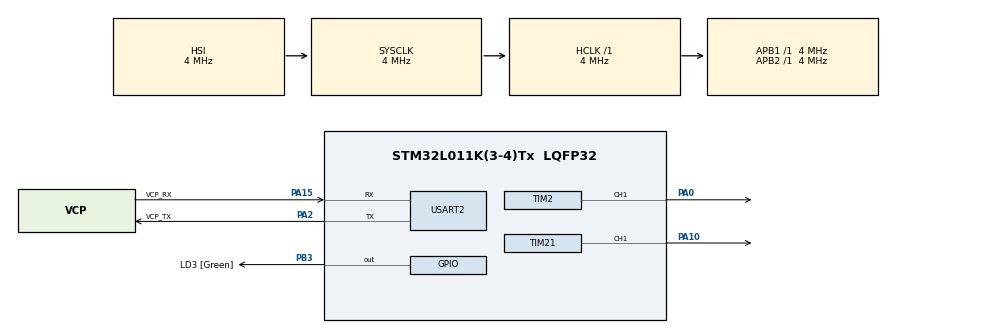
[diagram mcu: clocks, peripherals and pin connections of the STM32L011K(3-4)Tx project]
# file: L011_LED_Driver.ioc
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Mcu.Family=STM32L0
Mcu.Name=STM32L011K(3-4)Tx
Mcu.Package=LQFP32
PA0-CK_IN.Signal=S_TIM2_CH1
PA10.Signal=S_TIM21_CH1
PA13.GPIO_Label=TMS
PA13.Mode=Serial_Wire
PA13.Signal=SYS_SWDIO
PA14.GPIO_Label=TCK
PA14.Mode=Serial_Wire
PA14.Signal=SYS_SWCLK
PA15.GPIO_Label=VCP_RX
PA15.Mode=Asynchronous
PA15.Signal=USART2_RX
PA2.GPIO_Label=VCP_TX
PA2.Mode=Asynchronous
PA2.Signal=USART2_TX
PB3.GPIO_Label=LD3 [Green]
PB3.Signal=GPIO_Output
PC14-OSC32_IN.Mode=LSE-External-Oscillator
PC14-OSC32_IN.Signal=RCC_OSC32_IN
PC15-OSC32_OUT.Mode=LSE-External-Oscillator
PC15-OSC32_OUT.Signal=RCC_OSC32_OUT
ProjectManager.HeapSize=0x200
ProjectManager.StackSize=0x400
ProjectManager.TargetToolchain=STM32CubeIDE
RCC.ADCFreq_Value=4000000
RCC.AHBFreq_Value=4000000
RCC.APB1Freq_Value=4000000
RCC.APB1TimFreq_Value=4000000
RCC.APB2Freq_Value=4000000
RCC.APB2TimFreq_Value=4000000
RCC.HCLKFreq_Value=4000000
RCC.HSE_VALUE=8000000
RCC.HSI16_VALUE=16000000
RCC.HSI48_VALUE=48000000
RCC.HSIRCDiv=4
RCC.HSI_VALUE=4000000
RCC.MSIClockRange=RCC_MSIRANGE_6
RCC.MSI_VALUE=4194000
RCC.PLLMUL=RCC_PLLMUL_4
RCC.SYSCLKFreq_VALUE=4000000
RCC.SYSCLKSource=RCC_SYSCLKSOURCE_HSI
RCC.VCOOutputFreq_Value=16000000
SH.S_TIM21_CH1.0=TIM21_CH1,PWM Generation1 CH1
SH.S_TIM2_CH1.0=TIM2_CH1,PWM Generation1 CH1
TIM2.Channel-PWM\ Generation1\ CH1=TIM_CHANNEL_1
TIM2.Period=999
TIM2.Prescaler=3
TIM21.Channel-PWM\ Generation1\ CH1=TIM_CHANNEL_1
TIM21.Period=999
TIM21.Prescaler=3
USART2.VirtualMode-Asynchronous=VM_ASYNC
board=NUCLEO-L011K4

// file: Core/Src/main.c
/* USER CODE BEGIN Header */
/**
  ******************************************************************************
  * @file           : main.c
  * @brief          : Main program body
  ******************************************************************************
  * @attention
  *
  * Copyright (c) 2022 STMicroelectronics.
  * All rights reserved.
  *
  * This software is licensed under terms that can be found in the LICENSE file
  * in the root directory of this software component.
  * If no LICENSE file comes with this software, it is provided AS-IS.
  *
  ******************************************************************************
  */
/* USER CODE END Header */
#include "main.h"

TIM_HandleTypeDef htim2;
TIM_HandleTypeDef htim21;

UART_HandleTypeDef huart2;

void SystemClock_Config(void);
static void MX_GPIO_Init(void);
static void MX_USART2_UART_Init(void);
static void MX_TIM21_Init(void);
static void MX_TIM2_Init(void);

int main(void)
{

  /* MCU Configuration--------------------------------------------------------*/

  /* Reset of all peripherals, Initializes the Flash interface and the Systick. */
  HAL_Init();

  /* Configure the system clock */
  SystemClock_Config();

  /* Initialize all configured peripherals */
  MX_GPIO_Init();
  MX_USART2_UART_Init();
  MX_TIM21_Init();
  MX_TIM2_Init();
  /* USER CODE BEGIN 2 */

  /* Both PWM at 51% (dead time included) */
  __HAL_TIM_SET_COMPARE(&htim21, TIM_CHANNEL_1, 509);
  __HAL_TIM_SET_COMPARE(&htim2, TIM_CHANNEL_1, 509);

  /* Second PWM phase */
  __HAL_TIM_SET_COUNTER(&htim21, 499);

  /* Start both PWM */
  HAL_TIM_PWM_Start(&htim2, TIM_CHANNEL_1);
  HAL_TIM_PWM_Start(&htim21, TIM_CHANNEL_1);

  /* USER CODE END 2 */

  /* Infinite loop */
  while (1)
  {

  }
}

void SystemClock_Config(void)
{
  RCC_OscInitTypeDef RCC_OscInitStruct = {0};
  RCC_ClkInitTypeDef RCC_ClkInitStruct = {0};
  RCC_PeriphCLKInitTypeDef PeriphClkInit = {0};

  /** Configure the main internal regulator output voltage
  */
  __HAL_PWR_VOLTAGESCALING_CONFIG(PWR_REGULATOR_VOLTAGE_SCALE1);
  /** Initializes the RCC Oscillators according to the specified parameters
  * in the RCC_OscInitTypeDef structure.
  */
  RCC_OscInitStruct.OscillatorType = RCC_OSCILLATORTYPE_HSI;
  RCC_OscInitStruct.HSIState = RCC_HSI_DIV4;
  RCC_OscInitStruct.HSICalibrationValue = RCC_HSICALIBRATION_DEFAULT;
  RCC_OscInitStruct.PLL.PLLState = RCC_PLL_NONE;
  if (HAL_RCC_OscConfig(&RCC_OscInitStruct) != HAL_OK)
  {
    Error_Handler();
  }
  /** Initializes the CPU, AHB and APB buses clocks
  */
  RCC_ClkInitStruct.ClockType = RCC_CLOCKTYPE_HCLK|RCC_CLOCKTYPE_SYSCLK
                              |RCC_CLOCKTYPE_PCLK1|RCC_CLOCKTYPE_PCLK2;
  RCC_ClkInitStruct.SYSCLKSource = RCC_SYSCLKSOURCE_HSI;
  RCC_ClkInitStruct.AHBCLKDivider = RCC_SYSCLK_DIV1;
  RCC_ClkInitStruct.APB1CLKDivider = RCC_HCLK_DIV1;
  RCC_ClkInitStruct.APB2CLKDivider = RCC_HCLK_DIV1;

  if (HAL_RCC_ClockConfig(&RCC_ClkInitStruct, FLASH_LATENCY_0) != HAL_OK)
  {
    Error_Handler();
  }
  PeriphClkInit.PeriphClockSelection = RCC_PERIPHCLK_USART2;
  PeriphClkInit.Usart2ClockSelection = RCC_USART2CLKSOURCE_PCLK1;
  if (HAL_RCCEx_PeriphCLKConfig(&PeriphClkInit) != HAL_OK)
  {
    Error_Handler();
  }
}

static void MX_TIM2_Init(void)
{

  TIM_MasterConfigTypeDef sMasterConfig = {0};
  TIM_OC_InitTypeDef sConfigOC = {0};

  htim2.Instance = TIM2;
  htim2.Init.Prescaler = 3;
  htim2.Init.CounterMode = TIM_COUNTERMODE_UP;
  htim2.Init.Period = 999;
  htim2.Init.ClockDivision = TIM_CLOCKDIVISION_DIV1;
  htim2.Init.AutoReloadPreload = TIM_AUTORELOAD_PRELOAD_DISABLE;
  if (HAL_TIM_PWM_Init(&htim2) != HAL_OK)
  {
    Error_Handler();
  }
  sMasterConfig.MasterOutputTrigger = TIM_TRGO_RESET;
  sMasterConfig.MasterSlaveMode = TIM_MASTERSLAVEMODE_DISABLE;
  if (HAL_TIMEx_MasterConfigSynchronization(&htim2, &sMasterConfig) != HAL_OK)
  {
    Error_Handler();
  }
  sConfigOC.OCMode = TIM_OCMODE_PWM1;
  sConfigOC.Pulse = 0;
  sConfigOC.OCPolarity = TIM_OCPOLARITY_HIGH;
  sConfigOC.OCFastMode = TIM_OCFAST_DISABLE;
  if (HAL_TIM_PWM_ConfigChannel(&htim2, &sConfigOC, TIM_CHANNEL_1) != HAL_OK)
  {
    Error_Handler();
  }
  HAL_TIM_MspPostInit(&htim2);

}

static void MX_TIM21_Init(void)
{

  TIM_MasterConfigTypeDef sMasterConfig = {0};
  TIM_OC_InitTypeDef sConfigOC = {0};

  htim21.Instance = TIM21;
  htim21.Init.Prescaler = 3;
  htim21.Init.CounterMode = TIM_COUNTERMODE_UP;
  htim21.Init.Period = 999;
  htim21.Init.ClockDivision = TIM_CLOCKDIVISION_DIV1;
  htim21.Init.AutoReloadPreload = TIM_AUTORELOAD_PRELOAD_DISABLE;
  if (HAL_TIM_PWM_Init(&htim21) != HAL_OK)
  {
    Error_Handler();
  }
  sMasterConfig.MasterOutputTrigger = TIM_TRGO_RESET;
  sMasterConfig.MasterSlaveMode = TIM_MASTERSLAVEMODE_DISABLE;
  if (HAL_TIMEx_MasterConfigSynchronization(&htim21, &sMasterConfig) != HAL_OK)
  {
    Error_Handler();
  }
  sConfigOC.OCMode = TIM_OCMODE_PWM1;
  sConfigOC.Pulse = 0;
  sConfigOC.OCPolarity = TIM_OCPOLARITY_HIGH;
  sConfigOC.OCFastMode = TIM_OCFAST_DISABLE;
  if (HAL_TIM_PWM_ConfigChannel(&htim21, &sConfigOC, TIM_CHANNEL_1) != HAL_OK)
  {
    Error_Handler();
  }
  HAL_TIM_MspPostInit(&htim21);

}

static void MX_USART2_UART_Init(void)
{

  huart2.Instance = USART2;
  huart2.Init.BaudRate = 115200;
  huart2.Init.WordLength = UART_WORDLENGTH_8B;
  huart2.Init.StopBits = UART_STOPBITS_1;
  huart2.Init.Parity = UART_PARITY_NONE;
  huart2.Init.Mode = UART_MODE_TX_RX;
  huart2.Init.HwFlowCtl = UART_HWCONTROL_NONE;
  huart2.Init.OverSampling = UART_OVERSAMPLING_16;
  huart2.Init.OneBitSampling = UART_ONE_BIT_SAMPLE_DISABLE;
  huart2.AdvancedInit.AdvFeatureInit = UART_ADVFEATURE_NO_INIT;
  if (HAL_UART_Init(&huart2) != HAL_OK)
  {
    Error_Handler();
  }

}

static void MX_GPIO_Init(void)
{
  GPIO_InitTypeDef GPIO_InitStruct = {0};

  /* GPIO Ports Clock Enable */
  __HAL_RCC_GPIOC_CLK_ENABLE();
  __HAL_RCC_GPIOA_CLK_ENABLE();
  __HAL_RCC_GPIOB_CLK_ENABLE();

  /*Configure GPIO pin Output Level */
  HAL_GPIO_WritePin(LD3_GPIO_Port, LD3_Pin, GPIO_PIN_RESET);

  /*Configure GPIO pin : LD3_Pin */
  GPIO_InitStruct.Pin = LD3_Pin;
  GPIO_InitStruct.Mode = GPIO_MODE_OUTPUT_PP;
  GPIO_InitStruct.Pull = GPIO_NOPULL;
  GPIO_InitStruct.Speed = GPIO_SPEED_FREQ_LOW;
  HAL_GPIO_Init(LD3_GPIO_Port, &GPIO_InitStruct);

}

void Error_Handler(void)
{
  __disable_irq();
  while (1)
  {
  }
}
